AUTOSAR XML (schema 4-2-2)
package /ComponentTypes
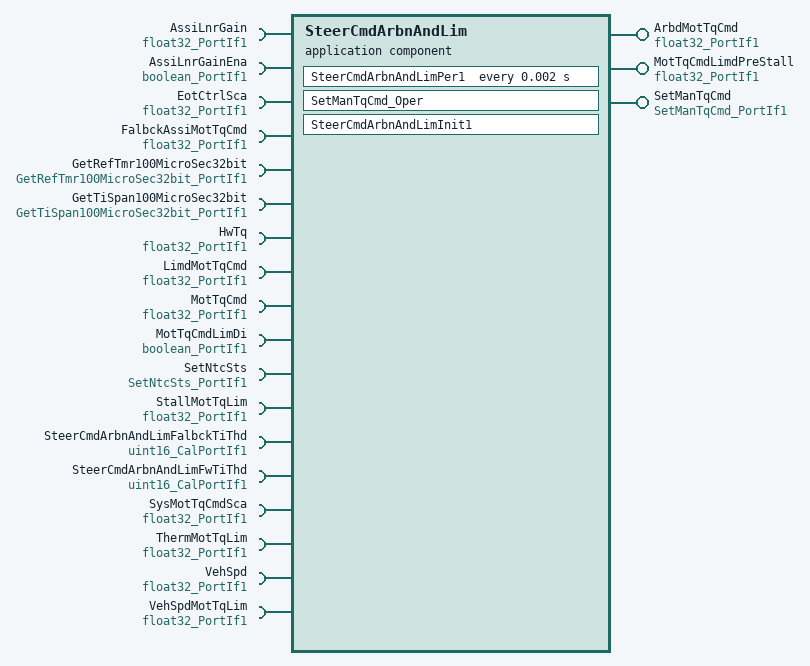
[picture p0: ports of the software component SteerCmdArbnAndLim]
  application sw component type SteerCmdArbnAndLim
    provide port ArbdMotTqCmd: nonqueued-sender-com-spec{data-element=Val, init-value=0}, provided-interface=float32_PortIf1
    provide port MotTqCmdLimdPreStall: nonqueued-sender-com-spec{data-element=Val, init-value=0}, provided-interface=float32_PortIf1
    provide port SetManTqCmd: server-com-spec{operation=Oper, queue-length=1}, provided-interface=SetManTqCmd_PortIf1
    18 x require port:
      AssiLnrGain: nonqueued-receiver-com-spec{data-element=Val, filter=data-filter-type=ALWAYS, init-value=0}, required-interface=float32_PortIf1
      AssiLnrGainEna: nonqueued-receiver-com-spec{data-element=Logl, filter=data-filter-type=ALWAYS, init-value=0}, required-interface=boolean_PortIf1
      EotCtrlSca: nonqueued-receiver-com-spec{data-element=Val, filter=data-filter-type=ALWAYS, init-value=1}, required-interface=float32_PortIf1
      FalbckAssiMotTqCmd: nonqueued-receiver-com-spec{data-element=Val, filter=data-filter-type=ALWAYS, init-value=0}, required-interface=float32_PortIf1
      GetRefTmr100MicroSec32bit: client-com-spec=Oper, required-interface=GetRefTmr100MicroSec32bit_PortIf1
      GetTiSpan100MicroSec32bit: client-com-spec=Oper, required-interface=GetTiSpan100MicroSec32bit_PortIf1
      HwTq: nonqueued-receiver-com-spec{data-element=Val, filter=data-filter-type=ALWAYS, init-value=0}, required-interface=float32_PortIf1
      LimdMotTqCmd: nonqueued-receiver-com-spec{data-element=Val, filter=data-filter-type=ALWAYS, init-value=0}, required-interface=float32_PortIf1
      MotTqCmd: nonqueued-receiver-com-spec{data-element=Val, filter=data-filter-type=ALWAYS, init-value=0}, required-interface=float32_PortIf1
      MotTqCmdLimDi: nonqueued-receiver-com-spec{data-element=Logl, filter=data-filter-type=ALWAYS, init-value=0}, required-interface=boolean_PortIf1
      SetNtcSts: client-com-spec=Oper, required-interface=SetNtcSts_PortIf1
      StallMotTqLim: nonqueued-receiver-com-spec{data-element=Val, filter=data-filter-type=ALWAYS, init-value=8.8}, required-interface=float32_PortIf1
      SteerCmdArbnAndLimFalbckTiThd: parameter-require-com-spec{init-value=1000, parameter=Val}, required-interface=uint16_CalPortIf1
      SteerCmdArbnAndLimFwTiThd: parameter-require-com-spec{init-value=100, parameter=Val}, required-interface=uint16_CalPortIf1
      SysMotTqCmdSca: nonqueued-receiver-com-spec{data-element=Val, filter=data-filter-type=ALWAYS, init-value=1}, required-interface=float32_PortIf1
      ThermMotTqLim: nonqueued-receiver-com-spec{data-element=Val, filter=data-filter-type=ALWAYS, init-value=8.8}, required-interface=float32_PortIf1
      VehSpd: nonqueued-receiver-com-spec{data-element=Val, filter=data-filter-type=ALWAYS, init-value=0}, required-interface=float32_PortIf1
      VehSpdMotTqLim: nonqueued-receiver-com-spec{data-element=Val, filter=data-filter-type=ALWAYS, init-value=8.8}, required-interface=float32_PortIf1
    behavior SteerCmdArbnAndLim_InternalBehavior
      ar-typed-per-instance-memorys:
        5 x data, all with sw-calibration-access=READ-ONLY:
          FalbckDebStVari: type=boolean
          FwDebStVari: type=boolean
          SteerCmdArbnAndLimDebStFalbck: type=float32
          SteerCmdArbnAndLimDebStFw: type=uint32
          SteerCmdArbnAndLimSt: type=uint8
      operation invoked event OIT_SetManTqCmd_Oper_SetManTqCmd_Oper: start-on-event=SetManTqCmd_Oper, operation=SetManTqCmd.Oper
      init event SteerCmdArbnAndLim_InitEvent: start-on-event=SteerCmdArbnAndLimInit1
      timing event TMT_SteerCmdArbnAndLimPer1: start-on-event=SteerCmdArbnAndLimPer1, period=0.002
      explicit-inter-runnable-variables:
        data ProcdManTqCmd: type=float32, init-value=0
        data ProcdManTqCmdEna: type=boolean, init-value=0
      port-api-options:
        enable-take-address=false, error-handling=NO-TRANSFORMER-ERROR-HANDLING, indirect-api=false, port=ArbdMotTqCmd
        enable-take-address=false, error-handling=NO-TRANSFORMER-ERROR-HANDLING, indirect-api=false, port=AssiLnrGain
        enable-take-address=false, error-handling=NO-TRANSFORMER-ERROR-HANDLING, indirect-api=false, port=AssiLnrGainEna
        enable-take-address=false, error-handling=NO-TRANSFORMER-ERROR-HANDLING, indirect-api=false, port=EotCtrlSca
        enable-take-address=false, error-handling=NO-TRANSFORMER-ERROR-HANDLING, indirect-api=false, port=FalbckAssiMotTqCmd
        enable-take-address=false, error-handling=NO-TRANSFORMER-ERROR-HANDLING, indirect-api=false, port=GetRefTmr100MicroSec32bit
        enable-take-address=false, error-handling=NO-TRANSFORMER-ERROR-HANDLING, indirect-api=false, port=GetTiSpan100MicroSec32bit
        enable-take-address=false, error-handling=NO-TRANSFORMER-ERROR-HANDLING, indirect-api=false, port=HwTq
        enable-take-address=false, error-handling=NO-TRANSFORMER-ERROR-HANDLING, indirect-api=false, port=LimdMotTqCmd
        enable-take-address=false, error-handling=NO-TRANSFORMER-ERROR-HANDLING, indirect-api=false, port=MotTqCmd
        enable-take-address=false, error-handling=NO-TRANSFORMER-ERROR-HANDLING, indirect-api=false, port=MotTqCmdLimDi
        enable-take-address=false, error-handling=NO-TRANSFORMER-ERROR-HANDLING, indirect-api=false, port=MotTqCmdLimdPreStall
        enable-take-address=false, error-handling=NO-TRANSFORMER-ERROR-HANDLING, indirect-api=false, port=SetManTqCmd
        enable-take-address=false, error-handling=NO-TRANSFORMER-ERROR-HANDLING, indirect-api=false, port=SetNtcSts
        enable-take-address=false, error-handling=NO-TRANSFORMER-ERROR-HANDLING, indirect-api=false, port=StallMotTqLim
        enable-take-address=false, error-handling=NO-TRANSFORMER-ERROR-HANDLING, indirect-api=false, port=SteerCmdArbnAndLimFalbckTiThd
        enable-take-address=false, error-handling=NO-TRANSFORMER-ERROR-HANDLING, indirect-api=false, port=SteerCmdArbnAndLimFwTiThd
        enable-take-address=false, error-handling=NO-TRANSFORMER-ERROR-HANDLING, indirect-api=false, port=SysMotTqCmdSca
        enable-take-address=false, error-handling=NO-TRANSFORMER-ERROR-HANDLING, indirect-api=false, port=ThermMotTqLim
        enable-take-address=false, error-handling=NO-TRANSFORMER-ERROR-HANDLING, indirect-api=false, port=VehSpd
        enable-take-address=false, error-handling=NO-TRANSFORMER-ERROR-HANDLING, indirect-api=false, port=VehSpdMotTqLim
      runnable SetManTqCmd_Oper: can-be-invoked-concurrently=true
        data-receive-point-by-arguments:
          access REC_VehSpd_Val: accessed-variable=VehSpd.Val
        written-local-variables:
          access WRITE_ProcdManTqCmd: accessed-variable=ProcdManTqCmd
          access WRITE_ProcdManTqCmdEna: accessed-variable=ProcdManTqCmdEna
      runnable SteerCmdArbnAndLimInit1
      runnable SteerCmdArbnAndLimPer1
        data-receive-point-by-arguments:
          12 x access:
            REC_AssiLnrGain_Val: accessed-variable=AssiLnrGain.Val
            REC_AssiLnrGainEna_Logl: accessed-variable=AssiLnrGainEna.Logl
            REC_EotCtrlSca_Val: accessed-variable=EotCtrlSca.Val
            REC_FalbckAssiMotTqCmd_Val: accessed-variable=FalbckAssiMotTqCmd.Val
            REC_HwTq_Val: accessed-variable=HwTq.Val
            REC_LimdMotTqCmd_Val: accessed-variable=LimdMotTqCmd.Val
            REC_MotTqCmd_Val: accessed-variable=MotTqCmd.Val
            REC_MotTqCmdLimDi_Logl: accessed-variable=MotTqCmdLimDi.Logl
            REC_StallMotTqLim_Val: accessed-variable=StallMotTqLim.Val
            REC_SysMotTqCmdSca_Val: accessed-variable=SysMotTqCmdSca.Val
            REC_ThermMotTqLim_Val: accessed-variable=ThermMotTqLim.Val
            REC_VehSpdMotTqLim_Val: accessed-variable=VehSpdMotTqLim.Val
        data-send-points:
          access SEND_ArbdMotTqCmd_Val: accessed-variable=ArbdMotTqCmd.Val
          access SEND_MotTqCmdLimdPreStall_Val: accessed-variable=MotTqCmdLimdPreStall.Val
        read-local-variables:
          access READ_ProcdManTqCmd: accessed-variable=ProcdManTqCmd
          access READ_ProcdManTqCmdEna: accessed-variable=ProcdManTqCmdEna
        sync call SC_GetRefTmr100MicroSec32bit_Oper: operation=GetRefTmr100MicroSec32bit.Oper, timeout=0
        sync call SC_GetTiSpan100MicroSec32bit_Oper: operation=GetTiSpan100MicroSec32bit.Oper, timeout=0
        sync call SC_SetNtcSts_PortIf1_Oper: operation=SetNtcSts.Oper, timeout=0
  swc implementation SteerCmdArbnAndLim_Implementation: behavior=SteerCmdArbnAndLim_InternalBehavior
    code-descriptors:
      code Default: artifact-descriptors=autosar-engineering-object={short-label=Default, category=SWSRC}
